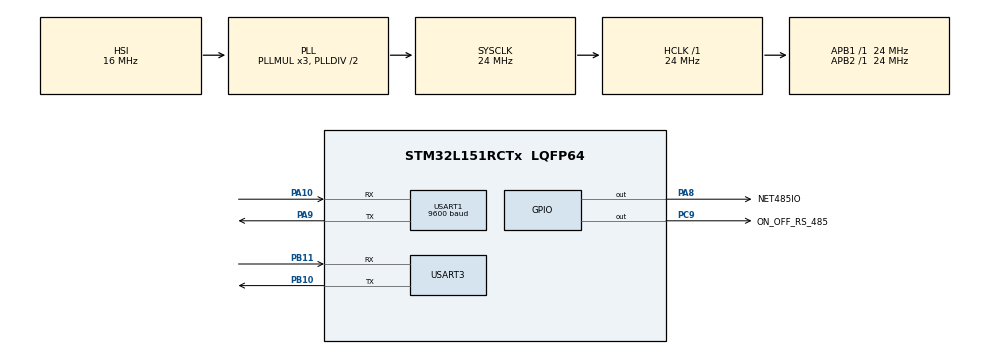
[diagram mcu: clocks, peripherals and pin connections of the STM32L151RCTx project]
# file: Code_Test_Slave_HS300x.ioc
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Mcu.Family=STM32L1
Mcu.Name=STM32L151RCTx
Mcu.Package=LQFP64
NVIC.PriorityGroup=NVIC_PRIORITYGROUP_4
NVIC.USART1_IRQn=true\:0\:0\:false\:false\:true\:true\:true\:true
NVIC.USART3_IRQn=true\:0\:0\:false\:false\:true\:true\:true\:true
PA10.Mode=Asynchronous
PA10.Signal=USART1_RX
PA13.Mode=Serial_Wire
PA13.Signal=SYS_JTMS-SWDIO
PA14.Mode=Serial_Wire
PA14.Signal=SYS_JTCK-SWCLK
PA8.GPIO_Label=NET485IO
PA8.GPIO_PuPd=GPIO_PULLDOWN
PA8.Signal=GPIO_Output
PA9.Mode=Asynchronous
PA9.Signal=USART1_TX
PB10.Mode=Asynchronous
PB10.Signal=USART3_TX
PB11.Mode=Asynchronous
PB11.Signal=USART3_RX
PC9.GPIO_Label=ON_OFF_RS_485
PC9.GPIO_PuPd=GPIO_PULLDOWN
PC9.Signal=GPIO_Output
ProjectManager.HeapSize=0x200
ProjectManager.StackSize=0x400
ProjectManager.TargetToolchain=EWARM V8.32
RCC.AHBFreq_Value=24000000
RCC.APB1Freq_Value=24000000
RCC.APB1TimFreq_Value=24000000
RCC.APB2Freq_Value=24000000
RCC.APB2TimFreq_Value=24000000
RCC.HCLKFreq_Value=24000000
RCC.HSE_VALUE=24000000
RCC.HSI_VALUE=16000000
RCC.LSE_VALUE=32768
RCC.MSI_VALUE=2097000
RCC.SYSCLKFreq_VALUE=24000000
RCC.SYSCLKSource=RCC_SYSCLKSOURCE_PLLCLK
RCC.VCOOutputFreq_Value=48000000
USART1.BaudRate=9600
USART1.VirtualMode=VM_ASYNC
USART3.VirtualMode=VM_ASYNC
board=custom

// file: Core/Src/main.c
/* USER CODE BEGIN Header */
/**
  ******************************************************************************
  * @file           : main.c
  * @brief          : Main program body
  ******************************************************************************
  * @attention
  *
  * Copyright (c) 2023 STMicroelectronics.
  * All rights reserved.
  *
  * This software is licensed under terms that can be found in the LICENSE file
  * in the root directory of this software component.
  * If no LICENSE file comes with this software, it is provided AS-IS.
  *
  ******************************************************************************
  */
/* USER CODE END Header */
#include "main.h"
#include "usart.h"
#include "gpio.h"

/* USER CODE BEGIN Includes */
#include "user_app_test_slave_hs300x.h"
/* USER CODE END Includes */

void SystemClock_Config(void);

int main(void)
{

  /* MCU Configuration--------------------------------------------------------*/

  /* Reset of all peripherals, Initializes the Flash interface and the Systick. */
  HAL_Init();

  /* Configure the system clock */
  SystemClock_Config();

  /* Initialize all configured peripherals */
  MX_GPIO_Init();
  MX_USART1_UART_Init();
  MX_USART3_UART_Init();
  /* USER CODE BEGIN 2 */
  Init_Uart_Module();
  Init_AppTest();
  HAL_Delay(1000);
  /* USER CODE END 2 */

  /* Infinite loop */
  while (1)
  {

    /* USER CODE BEGIN 3 */
    //AppTestSlaveHs300x();
	AppTestSlaveHs300x_Task();
  }
  /* USER CODE END 3 */
}

void SystemClock_Config(void)
{
  RCC_OscInitTypeDef RCC_OscInitStruct = {0};
  RCC_ClkInitTypeDef RCC_ClkInitStruct = {0};

  /** Configure the main internal regulator output voltage
  */
  __HAL_PWR_VOLTAGESCALING_CONFIG(PWR_REGULATOR_VOLTAGE_SCALE1);

  /** Initializes the RCC Oscillators according to the specified parameters
  * in the RCC_OscInitTypeDef structure.
  */
  RCC_OscInitStruct.OscillatorType = RCC_OSCILLATORTYPE_HSI;
  RCC_OscInitStruct.HSIState = RCC_HSI_ON;
  RCC_OscInitStruct.HSICalibrationValue = RCC_HSICALIBRATION_DEFAULT;
  RCC_OscInitStruct.PLL.PLLState = RCC_PLL_ON;
  RCC_OscInitStruct.PLL.PLLSource = RCC_PLLSOURCE_HSI;
  RCC_OscInitStruct.PLL.PLLMUL = RCC_PLL_MUL3;
  RCC_OscInitStruct.PLL.PLLDIV = RCC_PLL_DIV2;
  if (HAL_RCC_OscConfig(&RCC_OscInitStruct) != HAL_OK)
  {
    Error_Handler();
  }

  /** Initializes the CPU, AHB and APB buses clocks
  */
  RCC_ClkInitStruct.ClockType = RCC_CLOCKTYPE_HCLK|RCC_CLOCKTYPE_SYSCLK
                              |RCC_CLOCKTYPE_PCLK1|RCC_CLOCKTYPE_PCLK2;
  RCC_ClkInitStruct.SYSCLKSource = RCC_SYSCLKSOURCE_PLLCLK;
  RCC_ClkInitStruct.AHBCLKDivider = RCC_SYSCLK_DIV1;
  RCC_ClkInitStruct.APB1CLKDivider = RCC_HCLK_DIV1;
  RCC_ClkInitStruct.APB2CLKDivider = RCC_HCLK_DIV1;

  if (HAL_RCC_ClockConfig(&RCC_ClkInitStruct, FLASH_LATENCY_1) != HAL_OK)
  {
    Error_Handler();
  }
}

void Error_Handler(void)
{
  __disable_irq();
  while (1)
  {
  }
}
